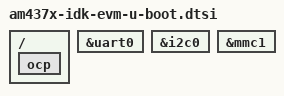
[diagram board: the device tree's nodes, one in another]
// SPDX-License-Identifier: GPL-2.0+
/*
 * Copyright (C) 2018 Texas Instruments Incorporated - http://www.ti.com/
 */

/{
	ocp {
		u-boot,dm-spl;
	};
};

&uart0 {
	u-boot,dm-spl;
};

&i2c0 {
	u-boot,dm-spl;
};

&mmc1 {
	u-boot,dm-spl;
};
